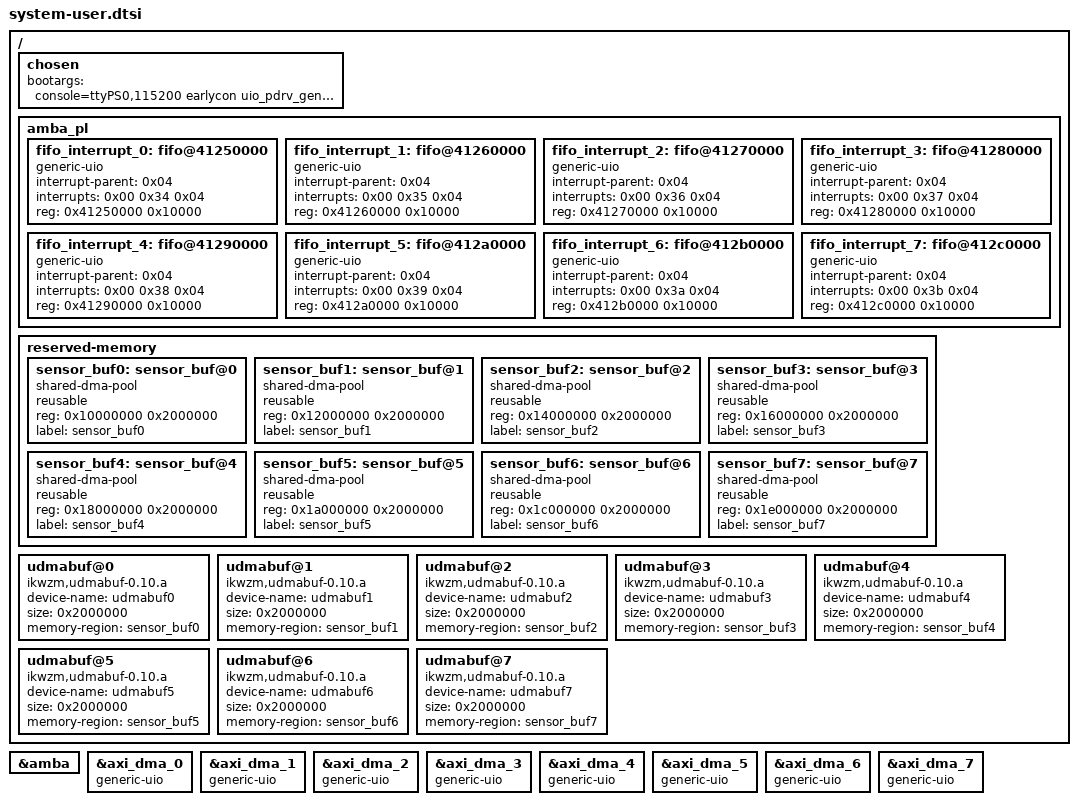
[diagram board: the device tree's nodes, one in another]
/include/ "system-conf.dtsi"
/ {
  chosen {
    bootargs = "console=ttyPS0,115200 earlycon uio_pdrv_genirq.of_id=generic-uio root=/dev/mmcblk0p2 rw rootwait";
  };

  amba_pl: amba_pl {
    fifo_interrupt_0: fifo@41250000 {
      #dma-cells = <0x01>;
      compatible = "generic-uio";
      interrupt-parent = <0x04>;
      interrupts = <0x00 0x34 0x04>;
      reg = <0x41250000 0x10000>;
    };

    fifo_interrupt_1: fifo@41260000 {
      #dma-cells = <0x01>;
      compatible = "generic-uio";
      interrupt-parent = <0x04>;
      interrupts = <0x00 0x35 0x04>;
      reg = <0x41260000 0x10000>;
    };

    fifo_interrupt_2: fifo@41270000 {
      #dma-cells = <0x01>;
      compatible = "generic-uio";
      interrupt-parent = <0x04>;
      interrupts = <0x00 0x36 0x04>;
      reg = <0x41270000 0x10000>;
    };

    fifo_interrupt_3: fifo@41280000 {
      #dma-cells = <0x01>;
      compatible = "generic-uio";
      interrupt-parent = <0x04>;
      interrupts = <0x00 0x37 0x04>;
      reg = <0x41280000 0x10000>;
    };

    fifo_interrupt_4: fifo@41290000 {
      #dma-cells = <0x01>;
      compatible = "generic-uio";
      interrupt-parent = <0x04>;
      interrupts = <0x00 0x38 0x04>;
      reg = <0x41290000 0x10000>;
    };

    fifo_interrupt_5: fifo@412a0000 {
      #dma-cells = <0x01>;
      compatible = "generic-uio";
      interrupt-parent = <0x04>;
      interrupts = <0x00 0x39 0x04>;
      reg = <0x412a0000 0x10000>;
    };

    fifo_interrupt_6: fifo@412b0000 {
      #dma-cells = <0x01>;
      compatible = "generic-uio";
      interrupt-parent = <0x04>;
      interrupts = <0x00 0x3a 0x04>;
      reg = <0x412b0000 0x10000>;
    };

    fifo_interrupt_7: fifo@412c0000 {
      #dma-cells = <0x01>;
      compatible = "generic-uio";
      interrupt-parent = <0x04>;
      interrupts = <0x00 0x3b 0x04>;
      reg = <0x412c0000 0x10000>;
    };
  };

  reserved-memory {
    #address-cells = <1>;
    #size-cells = <1>;
    ranges;
    sensor_buf0: sensor_buf@0 {
      compatible = "shared-dma-pool";
      reusable;
      reg = <0x10000000 0x2000000>;
      label = "sensor_buf0";
    };
    sensor_buf1: sensor_buf@1 {
      compatible = "shared-dma-pool";
      reusable;
      reg = <0x12000000 0x2000000>;
      label = "sensor_buf1";
    };
    sensor_buf2: sensor_buf@2 {
      compatible = "shared-dma-pool";
      reusable;
      reg = <0x14000000 0x2000000>;
      label = "sensor_buf2";
    };
    sensor_buf3: sensor_buf@3 {
      compatible = "shared-dma-pool";
      reusable;
      reg = <0x16000000 0x2000000>;
      label = "sensor_buf3";
    };
    sensor_buf4: sensor_buf@4 {
      compatible = "shared-dma-pool";
      reusable;
      reg = <0x18000000 0x2000000>;
      label = "sensor_buf4";
    };
    sensor_buf5: sensor_buf@5 {
      compatible = "shared-dma-pool";
      reusable;
      reg = <0x1a000000 0x2000000>;
      label = "sensor_buf5";
    };
    sensor_buf6: sensor_buf@6 {
      compatible = "shared-dma-pool";
      reusable;
      reg = <0x1c000000 0x2000000>;
      label = "sensor_buf6";
    };
    sensor_buf7: sensor_buf@7 {
      compatible = "shared-dma-pool";
      reusable;
      reg = <0x1e000000 0x2000000>;
      label = "sensor_buf7";
    };
  };

  udmabuf@0 {
    compatible = "ikwzm,udmabuf-0.10.a";
    device-name = "udmabuf0";
    size = <0x2000000>; // 32MiB
    memory-region = <&sensor_buf0>;
  };
  udmabuf@1 {
    compatible = "ikwzm,udmabuf-0.10.a";
    device-name = "udmabuf1";
    size = <0x2000000>; // 32MiB
    memory-region = <&sensor_buf1>;
  };
  udmabuf@2 {
    compatible = "ikwzm,udmabuf-0.10.a";
    device-name = "udmabuf2";
    size = <0x2000000>; // 32MiB
    memory-region = <&sensor_buf2>;
  };
  udmabuf@3 {
    compatible = "ikwzm,udmabuf-0.10.a";
    device-name = "udmabuf3";
    size = <0x2000000>; // 32MiB
    memory-region = <&sensor_buf3>;
  };
  udmabuf@4 {
    compatible = "ikwzm,udmabuf-0.10.a";
    device-name = "udmabuf4";
    size = <0x2000000>; // 32MiB
    memory-region = <&sensor_buf4>;
  };
  udmabuf@5 {
    compatible = "ikwzm,udmabuf-0.10.a";
    device-name = "udmabuf5";
    size = <0x2000000>; // 32MiB
    memory-region = <&sensor_buf5>;
  };
  udmabuf@6 {
    compatible = "ikwzm,udmabuf-0.10.a";
    device-name = "udmabuf6";
    size = <0x2000000>; // 32MiB
    memory-region = <&sensor_buf6>;
  };
  udmabuf@7 {
    compatible = "ikwzm,udmabuf-0.10.a";
    device-name = "udmabuf7";
    size = <0x2000000>; // 32MiB
    memory-region = <&sensor_buf7>;
  };
};

&amba {
  /delete-node/ dmac@f8003000;
};

&axi_dma_0 {
  compatible = "generic-uio";
  /delete-property/ clock-names;
  /delete-property/ clocks;
  /delete-property/ interrupt-names;
  /delete-property/ xlnx,addrwidth;
  /delete-property/ xlnx,sg-length-width;
  /delete-node/ dma-channel@40400030;
};
&axi_dma_1 {
  compatible = "generic-uio";
  /delete-property/ clock-names;
  /delete-property/ clocks;
  /delete-property/ interrupt-names;
  /delete-property/ xlnx,addrwidth;
  /delete-property/ xlnx,sg-length-width;
  /delete-node/ dma-channel@40410030;
};
&axi_dma_2 {
  compatible = "generic-uio";
  /delete-property/ clock-names;
  /delete-property/ clocks;
  /delete-property/ interrupt-names;
  /delete-property/ xlnx,addrwidth;
  /delete-property/ xlnx,sg-length-width;
  /delete-node/ dma-channel@40420030;
};
&axi_dma_3 {
  compatible = "generic-uio";
  /delete-property/ clock-names;
  /delete-property/ clocks;
  /delete-property/ interrupt-names;
  /delete-property/ xlnx,addrwidth;
  /delete-property/ xlnx,sg-length-width;
  /delete-node/ dma-channel@40430030;
};
&axi_dma_4 {
  compatible = "generic-uio";
  /delete-property/ clock-names;
  /delete-property/ clocks;
  /delete-property/ interrupt-names;
  /delete-property/ xlnx,addrwidth;
  /delete-property/ xlnx,sg-length-width;
  /delete-node/ dma-channel@40440030;
};
&axi_dma_5 {
  compatible = "generic-uio";
  /delete-property/ clock-names;
  /delete-property/ clocks;
  /delete-property/ interrupt-names;
  /delete-property/ xlnx,addrwidth;
  /delete-property/ xlnx,sg-length-width;
  /delete-node/ dma-channel@40450030;
};
&axi_dma_6 {
  compatible = "generic-uio";
  /delete-property/ clock-names;
  /delete-property/ clocks;
  /delete-property/ interrupt-names;
  /delete-property/ xlnx,addrwidth;
  /delete-property/ xlnx,sg-length-width;
  /delete-node/ dma-channel@40460030;
};
&axi_dma_7 {
  compatible = "generic-uio";
  /delete-property/ clock-names;
  /delete-property/ clocks;
  /delete-property/ interrupt-names;
  /delete-property/ xlnx,addrwidth;
  /delete-property/ xlnx,sg-length-width;
  /delete-node/ dma-channel@40470030;
};
